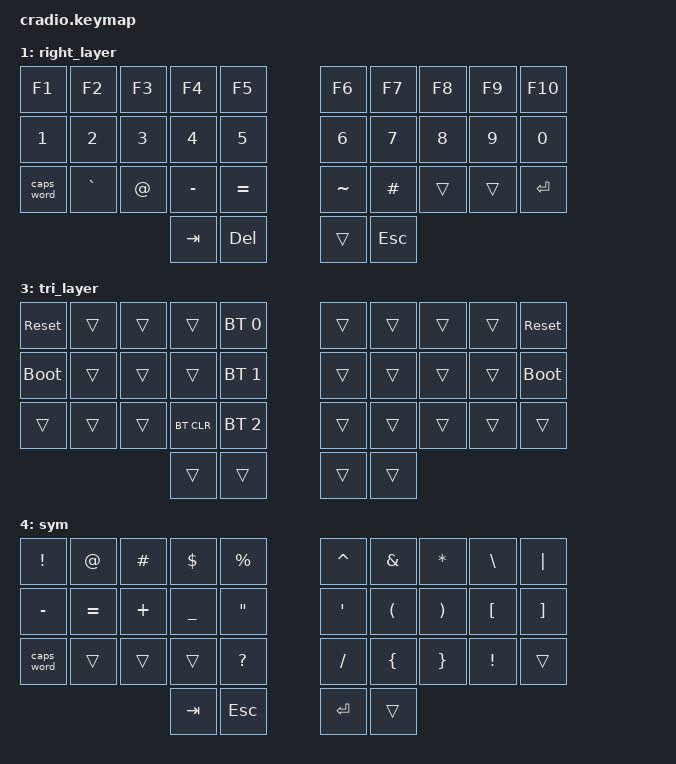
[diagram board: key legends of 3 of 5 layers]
// Copyright (c) 2022 The ZMK Contributors
// SPDX-License-Identifier: MIT

#include <behaviors.dtsi>
#include <dt-bindings/zmk/keys.h>
#include <dt-bindings/zmk/bt.h>

// Home row mods macro
#define HRML(k1,k2,k3,k4) &ht LGUI k1  &ht LALT k2  &ht LCTRL k3  &ht LSHFT k4
#define HRMR(k1,k2,k3,k4) &ht RSHFT k1  &ht RCTRL k2  &ht RALT k3  &ht RGUI k4

/ {
    behaviors {
        ht: hold_tap {
            compatible = "zmk,behavior-hold-tap";
            #binding-cells = <2>;
            flavor = "tap-preferred";
            tapping-term-ms = <220>;
            quick-tap-ms = <150>;
            require-prior-idle-ms = <100>;
            bindings = <&kp>, <&kp>;
        };
    };

    conditional_layers {
        compatible = "zmk,conditional-layers";
        tri_layer {
            if-layers = <1 2>;
            then-layer = <3>;
        };
    }; 

    combos {
        compatible = "zmk,combos";
        combo_col {
            timeout-ms = <50>;
            key-positions = <23 26>;
            bindings = <&kp COLON>;
        };
        combo_esc {
            timeout-ms = <50>;
            key-positions = <14 15>;
            bindings = <&kp ESC>;
        };
    };
    
    keymap {
        compatible = "zmk,keymap";
        default_layer {
            bindings = <
        //╭──────────┬──────────┬──────────┬──────────┬──────────╮     ╭──────────┬──────────┬──────────┬──────────┬──────────╮
        //│  Q       │  W       │  F       │  P       │  B       │   │  J       │  L       │  U       │  Y       │  ;       │
            &kp Q      &kp W      &kp F      &kp P      &kp B          &kp J      &kp L      &kp U      &kp Y      &kp SEMI
        //├──────────┼──────────┼──────────┼──────────┼──────────┤   ├──────────┼──────────┼──────────┼──────────┼──────────┤
        //│  A       │  R       │  S       │  T       │  G       │   │  M       │  N       │  E       │  I       │  O       │
            HRML(A,        R,         S,         T)     &lt 2 G          &kp M      HRMR(N,        E,         I,        O)
        //├──────────┼──────────┼──────────┼──────────┼──────────┤   ├──────────┼──────────┼──────────┼──────────┼──────────┤
        //│  Z       │  X       │  C       │  D       │  V       │   │  K       │  H       │ , <      │ . >      │ / ?      │
            &kp Z      &kp X      &kp C      &kp D      &kp V          &kp K      &kp H      &kp COMMA  &kp DOT    &kp FSLH
        //╰──────────┴──────────┴──────────┼──────────┼──────────┤   ├──────────┼──────────┼──────────┴──────────┴──────────╯
                                            &lt 2 TAB   &lt 1 BSPC    &lt 4 SPACE  &lt 1 ENTER
        //                                 ╰──────────┴──────────╯      ╰──────────┴──────────╯
            >;
        };

        right_layer {
            bindings = <
&kp F1        &kp F2        &kp F3        &kp F4        &kp F5     &kp F6        &kp F7    &kp F8   &kp F9        &kp F10
&kp NUMBER_1  &kp NUMBER_2  &kp NUMBER_3  &kp NUMBER_4  &kp N5     &kp NUMBER_6  &kp N7    &kp N8   &kp NUMBER_9  &kp N0
&caps_word        &kp GRAVE     &kp AT_SIGN   &kp MINUS     &kp EQUAL  &kp TILDE     &kp HASH  &trans  &trans      &kp ENTER
                                          &kp TAB        &kp DELETE    &trans        &kp ESC
            >; 
        };

        left_layer {
            bindings = <
        //╭──────────┬──────────┬──────────┬──────────┬──────────╮   ╭──────────┬──────────┬──────────┬──────────┬──────────╮
        //│          │  [       │  {       │  }       │          │   │  ^       │  (       │  )       │  ]       │  ~       │
            &trans     &kp LBKT   &kp LBRC   &kp RBRC   &trans         &kp PAGE_UP  &kp LPAR   &kp RPAR   &kp RBKT   &kp TILDE
        //├──────────┼──────────┼──────────┼──────────┼──────────┤   ├──────────┼──────────┼──────────┼──────────┼──────────┤
        //│  !       │  @       │  #       │  $       │  %       │   │  *       │  -       │  =       │  \       │  `       │
            &kp EXCL   &kp AT     &kp HASH   &kp DLLR   &kp PRCNT      &kp LEFT_ARROW  &kp DOWN_ARROW  &kp UP_ARROW  &kp RIGHT_ARROW
        //├──────────┼──────────┼──────────┼──────────┼──────────┤   ├──────────┼──────────┼──────────┼──────────┼──────────┤
        //│          │          │          │          │          │   │  &       │  _       │  +       │  │       │          │
            &trans     &trans     &trans     &trans     &trans         &kp PAGE_DOWN   &kp UNDER  &kp PLUS   &kp PIPE   &trans
        //╰──────────┴──────────┴──────────┼──────────┼──────────┤   ├──────────┼──────────┼──────────┴──────────┴──────────╯
                                             &trans     &trans         &kp ENTER     &trans
        //                                 ╰──────────┴──────────╯   ╰──────────┴──────────╯
            >;
        };

        tri_layer {
            bindings = <
        //╭──────────┬──────────┬──────────┬──────────┬──────────╮   ╭──────────┬──────────┬──────────┬──────────┬──────────╮
        //│ RESET    │          │          │          │PROFILE 0 │   │          │          │          │          │  RESET   │
           &sys_reset  &trans     &trans     &trans    &bt BT_SEL 0    &trans     &trans     &trans     &trans    &sys_reset
        //├──────────┼──────────┼──────────┼──────────┼──────────┤   ├──────────┼──────────┼──────────┼──────────┼──────────┤
        //│BOOTLOADER│          │          │          │PROFILE 1 │   │          │          │          │          │BOOTLOADER│
          &bootloader  &trans     &trans     &trans    &bt BT_SEL 1    &trans     &trans     &trans     &trans    &bootloader
        //├──────────┼──────────┼──────────┼──────────┼──────────┤   ├──────────┼──────────┼──────────┼──────────┼──────────┤
        //│          │          │          │ CLEAR BT │PROFILE 2 │   │          │          │          │          │          │
            &trans     &trans     &trans    &bt BT_CLR &bt BT_SEL 2    &trans     &trans     &trans     &trans     &trans
        //╰──────────┴──────────┴──────────┼──────────┼──────────┤   ├──────────┼──────────┼──────────┴──────────┴──────────╯
                                             &trans     &trans         &trans     &trans
        //                                 ╰──────────┴──────────╯   ╰──────────┴──────────╯
            >;
        };

    sym {
            bindings = <
&kp EXCL    &kp AT_SIGN  &kp HASH  &kp DOLLAR  &kp PERCENT        &kp CARET         &kp AMPS              &kp ASTRK              &kp BACKSLASH     &kp PIPE
&kp MINUS   &kp EQUAL    &kp PLUS  &kp UNDER   &kp DOUBLE_QUOTES  &kp SINGLE_QUOTE  &kp LEFT_PARENTHESIS  &kp RIGHT_PARENTHESIS  &kp LEFT_BRACKET  &kp RIGHT_BRACKET
&caps_word  &trans       &trans    &trans      &kp QUESTION       &kp SLASH         &kp LEFT_BRACE        &kp RIGHT_BRACE        &kp EXCL          &trans
                                   &kp TAB     &kp ESCAPE         &kp ENTER         &trans
            >;
        };
    };
};
